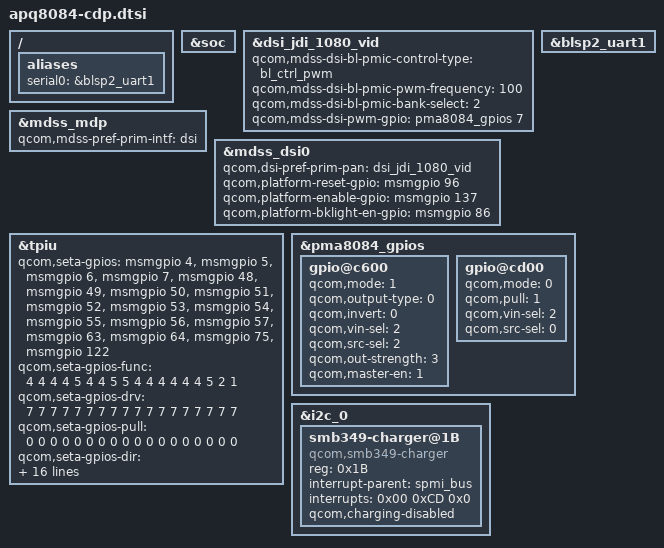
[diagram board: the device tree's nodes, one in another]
/* Copyright (c) 2013, The Linux Foundation. All rights reserved.
 *
 * This program is free software; you can redistribute it and/or modify
 * it under the terms of the GNU General Public License version 2 and
 * only version 2 as published by the Free Software Foundation.
 *
 * This program is distributed in the hope that it will be useful,
 * but WITHOUT ANY WARRANTY; without even the implied warranty of
 * MERCHANTABILITY or FITNESS FOR A PARTICULAR PURPOSE.  See the
 * GNU General Public License for more details.
 */

/ {
	aliases {
		serial0 = &blsp2_uart1;
	};
};

&soc {
};

/include/ "dsi-panel-jdi-1080p-video.dtsi"
&dsi_jdi_1080_vid {
	qcom,mdss-dsi-bl-pmic-control-type = "bl_ctrl_pwm";
	qcom,mdss-dsi-bl-pmic-pwm-frequency = <100>;
	qcom,mdss-dsi-bl-pmic-bank-select = <2>;
	qcom,mdss-dsi-pwm-gpio = <&pma8084_gpios 7 0>;
};

&mdss_mdp {
	qcom,mdss-pref-prim-intf = "dsi";
};

&mdss_dsi0 {
	qcom,dsi-pref-prim-pan = <&dsi_jdi_1080_vid>;
	qcom,platform-reset-gpio = <&msmgpio 96 0>;
	qcom,platform-enable-gpio = <&msmgpio 137 0>;
	qcom,platform-bklight-en-gpio = <&msmgpio 86 0>;
};

&blsp2_uart1 {
	status = "ok";
};

/* CoreSight */
&tpiu {
	qcom,seta-gpios = <&msmgpio 4 0>,
			  <&msmgpio 5 0>,
			  <&msmgpio 6 0>,
			  <&msmgpio 7 0>,
			  <&msmgpio 48 0>,
			  <&msmgpio 49 0>,
			  <&msmgpio 50 0>,
			  <&msmgpio 51 0>,
			  <&msmgpio 52 0>,
			  <&msmgpio 53 0>,
			  <&msmgpio 54 0>,
			  <&msmgpio 55 0>,
			  <&msmgpio 56 0>,
			  <&msmgpio 57 0>,
			  <&msmgpio 63 0>,
			  <&msmgpio 64 0>,
			  <&msmgpio 75 0>,
			  <&msmgpio 122 0>;
	qcom,seta-gpios-func = <4 4 4 4 5 4 4 5 5 4 4 4 4 4 4 5 2 1>;
	qcom,seta-gpios-drv =  <7 7 7 7 7 7 7 7 7 7 7 7 7 7 7 7 7 7>;
	qcom,seta-gpios-pull = <0 0 0 0 0 0 0 0 0 0 0 0 0 0 0 0 0 0>;
	qcom,seta-gpios-dir =  <2 2 2 2 2 2 2 2 2 2 2 2 2 2 2 2 2 2>;

	qcom,setb-gpios = <&msmgpio 10 0>,
			  <&msmgpio 11 0>,
			  <&msmgpio 29 0>,
			  <&msmgpio 30 0>,
			  <&msmgpio 39 0>,
			  <&msmgpio 40 0>,
			  <&msmgpio 43 0>,
			  <&msmgpio 44 0>,
			  <&msmgpio 45 0>,
			  <&msmgpio 46 0>,
			  <&msmgpio 67 0>,
			  <&msmgpio 68 0>,
			  <&msmgpio 69 0>,
			  <&msmgpio 70 0>,
			  <&msmgpio 71 0>,
			  <&msmgpio 72 0>,
			  <&msmgpio 102 0>,
			  <&msmgpio 121 0>;
	qcom,setb-gpios-func = <4 4 5 4 4 4 4 4 4 4 3 3 2 4 3 3 2 1>;
	qcom,setb-gpios-drv =  <7 7 7 7 7 7 7 7 7 7 7 7 7 7 7 7 7 7>;
	qcom,setb-gpios-pull = <0 0 0 0 0 0 0 0 0 0 0 0 0 0 0 0 0 0>;
	qcom,setb-gpios-dir =  <2 2 2 2 2 2 2 2 2 2 2 2 2 2 2 2 2 2>;
};

&pma8084_gpios {
	gpio@c600 { /* GPIO 7 */
		/* Backlight PWM */
		qcom,mode = <1>;		/* Digital output */
		qcom,output-type = <0>;		/* CMOS logic */
		qcom,invert = <0>;		/* Do not invert the output */
		qcom,vin-sel = <2>;		/* PMA8084 S4 = 1.8 V */
		qcom,src-sel = <2>;		/* Special Function 1 = LPG 3 */
		qcom,out-strength = <3>;	/* High drive strength */
		qcom,master-en = <1>;
	};

	gpio@cd00 { /* GPIO 14 */
		qcom,mode = <0>;
		qcom,pull = <1>;
		qcom,vin-sel = <2>;
		qcom,src-sel = <0>;
	};
};

&i2c_0 {
	smb349-charger@1B {
		compatible = "qcom,smb349-charger";
		reg = <0x1B>;
		interrupt-parent = <&spmi_bus>;
		interrupts = <0x00 0xCD 0x0>; /* PMIC8084 GPIO 14 */
		qcom,charging-disabled;
	};
};
